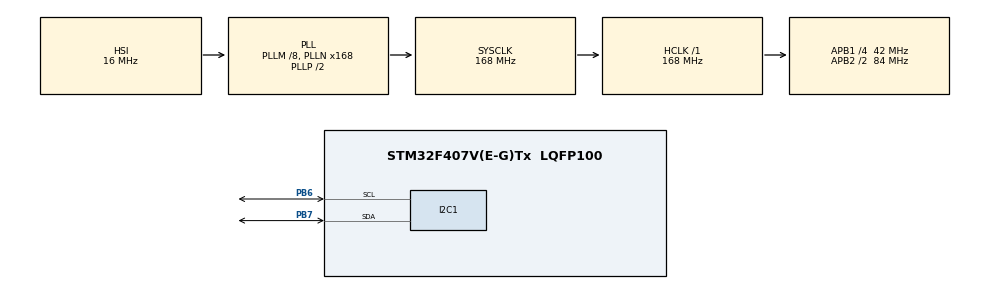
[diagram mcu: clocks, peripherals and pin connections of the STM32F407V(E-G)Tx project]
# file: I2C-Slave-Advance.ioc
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Mcu.Family=STM32F4
Mcu.Name=STM32F407V(E-G)Tx
Mcu.Package=LQFP100
NVIC.I2C1_ER_IRQn=true\:0\:0\:false\:false\:true\:true\:true
NVIC.I2C1_EV_IRQn=true\:0\:0\:false\:false\:true\:true\:true
NVIC.PriorityGroup=NVIC_PRIORITYGROUP_4
PB6.Mode=I2C
PB6.Signal=I2C1_SCL
PB7.Mode=I2C
PB7.Signal=I2C1_SDA
ProjectManager.HeapSize=0x200
ProjectManager.StackSize=0x400
ProjectManager.TargetToolchain=MDK-ARM V5.27
RCC.48MHZClocksFreq_Value=84000000
RCC.AHBFreq_Value=168000000
RCC.APB1CLKDivider=RCC_HCLK_DIV4
RCC.APB1Freq_Value=42000000
RCC.APB1TimFreq_Value=84000000
RCC.APB2CLKDivider=RCC_HCLK_DIV2
RCC.APB2Freq_Value=84000000
RCC.APB2TimFreq_Value=168000000
RCC.CortexFreq_Value=168000000
RCC.HCLKFreq_Value=168000000
RCC.HSE_VALUE=25000000
RCC.HSI_VALUE=16000000
RCC.LSE_VALUE=32768
RCC.PLLM=8
RCC.PLLN=168
RCC.SYSCLKFreq_VALUE=168000000
RCC.SYSCLKSource=RCC_SYSCLKSOURCE_PLLCLK
RCC.VCOOutputFreq_Value=336000000
board=custom

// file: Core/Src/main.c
/* USER CODE BEGIN Header */
/**
  ******************************************************************************
  * @file           : main.c
  * @brief          : Main program body
  ******************************************************************************
  * @attention
  *
  * <h2><center>&copy; Copyright (c) 2024 STMicroelectronics.
  * All rights reserved.</center></h2>
  *
  * This software component is licensed by ST under BSD 3-Clause license,
  * the "License"; You may not use this file except in compliance with the
  * License. You may obtain a copy of the License at:
  *                        opensource.org/licenses/BSD-3-Clause
  *
  ******************************************************************************
  */
/* USER CODE END Header */
#include "main.h"
#include "i2c.h"
#include "gpio.h"

/* USER CODE BEGIN Includes */
#include "ALCD.h"
/* USER CODE END Includes */

/* USER CODE BEGIN PTD */
typedef enum {
  Command_Request_Write,
  Command_Request_Read,
} Command_Request;

typedef struct {
  uint8_t       Request;
  uint8_t       Address;
  uint8_t       Len;
} Command;

typedef struct {
  uint32_t      Id;
  uint32_t      Counter;
} Parameters;

typedef enum {
  ComState_Command,
  ComState_Payload,
} ComState;
/* USER CODE END PTD */

/* USER CODE BEGIN PV */
static Parameters txParam = {0};
static Parameters rxParam = {0};
static Command    command = {0};
static ComState   comState;
static uint8_t    rxFlag = 0;
static uint8_t    readRequest = 0;
/* USER CODE END PV */

void SystemClock_Config(void);

int main(void)
{
  /* USER CODE BEGIN 1 */
  uint32_t nextCount = 0;
  /* USER CODE END 1 */

  /* MCU Configuration--------------------------------------------------------*/

  /* Reset of all peripherals, Initializes the Flash interface and the Systick. */
  HAL_Init();

  /* Configure the system clock */
  SystemClock_Config();

  /* Initialize all configured peripherals */
  MX_GPIO_Init();
  MX_I2C1_Init();
  /* USER CODE BEGIN 2 */
  ALCD_init(16, 2);
  ALCD_clear();
  /* USER CODE END 2 */

  /* Infinite loop */
  /* USER CODE BEGIN WHILE */
  comState = ComState_Command;
  HAL_I2C_Slave_Receive_IT(&hi2c1, (uint8_t*) &command, sizeof(Command));
  while (1)
  {
    if (nextCount<= HAL_GetTick()) {
      nextCount = HAL_GetTick() + 1000;

      txParam.Id = 101;
      txParam.Counter++;
      ALCD_printfXY(0, 0, "TCnt:%-5u", txParam.Counter);
    }

    if (rxFlag) {
      rxFlag = 0;

      ALCD_printfXY(0, 1, "RCnt:%-5u", rxParam.Counter);
    }
    /* USER CODE END WHILE */

  }
}

void SystemClock_Config(void)
{
  RCC_OscInitTypeDef RCC_OscInitStruct = {0};
  RCC_ClkInitTypeDef RCC_ClkInitStruct = {0};

  /** Configure the main internal regulator output voltage
  */
  __HAL_RCC_PWR_CLK_ENABLE();
  __HAL_PWR_VOLTAGESCALING_CONFIG(PWR_REGULATOR_VOLTAGE_SCALE1);
  /** Initializes the RCC Oscillators according to the specified parameters
  * in the RCC_OscInitTypeDef structure.
  */
  RCC_OscInitStruct.OscillatorType = RCC_OSCILLATORTYPE_HSI;
  RCC_OscInitStruct.HSIState = RCC_HSI_ON;
  RCC_OscInitStruct.HSICalibrationValue = RCC_HSICALIBRATION_DEFAULT;
  RCC_OscInitStruct.PLL.PLLState = RCC_PLL_ON;
  RCC_OscInitStruct.PLL.PLLSource = RCC_PLLSOURCE_HSI;
  RCC_OscInitStruct.PLL.PLLM = 8;
  RCC_OscInitStruct.PLL.PLLN = 168;
  RCC_OscInitStruct.PLL.PLLP = RCC_PLLP_DIV2;
  RCC_OscInitStruct.PLL.PLLQ = 4;
  if (HAL_RCC_OscConfig(&RCC_OscInitStruct) != HAL_OK)
  {
    Error_Handler();
  }
  /** Initializes the CPU, AHB and APB buses clocks
  */
  RCC_ClkInitStruct.ClockType = RCC_CLOCKTYPE_HCLK|RCC_CLOCKTYPE_SYSCLK
                              |RCC_CLOCKTYPE_PCLK1|RCC_CLOCKTYPE_PCLK2;
  RCC_ClkInitStruct.SYSCLKSource = RCC_SYSCLKSOURCE_PLLCLK;
  RCC_ClkInitStruct.AHBCLKDivider = RCC_SYSCLK_DIV1;
  RCC_ClkInitStruct.APB1CLKDivider = RCC_HCLK_DIV4;
  RCC_ClkInitStruct.APB2CLKDivider = RCC_HCLK_DIV2;

  if (HAL_RCC_ClockConfig(&RCC_ClkInitStruct, FLASH_LATENCY_5) != HAL_OK)
  {
    Error_Handler();
  }
}

/* USER CODE BEGIN 4 */
void HAL_I2C_SlaveRxCpltCallback(I2C_HandleTypeDef* hi2c) {
  switch (comState) {
    case ComState_Command:
      switch (command.Request) {
        case Command_Request_Read:
          comState = ComState_Payload;
          HAL_I2C_Slave_Transmit_IT(&hi2c1, &((uint8_t*) &txParam)[command.Address], command.Len);
          break;
        case Command_Request_Write:
          comState = ComState_Payload;
          HAL_I2C_Slave_Receive_IT(&hi2c1, &((uint8_t*) &rxParam)[command.Address], command.Len);
          break;
      }
      break;
    case ComState_Payload:
      rxFlag = 1;
      comState = ComState_Command;
      HAL_I2C_Slave_Receive_IT(&hi2c1, (uint8_t*) &command, sizeof(Command));
      break;
  }
}
void HAL_I2C_SlaveTxCpltCallback(I2C_HandleTypeDef* hi2c) {
  switch (comState) {
    case ComState_Command:

      break;
    case ComState_Payload:
      comState = ComState_Command;
      HAL_I2C_Slave_Receive_IT(&hi2c1, (uint8_t*) &command, sizeof(Command));
      break;
  }
}
/* USER CODE END 4 */

void Error_Handler(void)
{
  __disable_irq();
  while (1)
  {
  }
}

/************************ (C) COPYRIGHT STMicroelectronics *****END OF FILE****/
